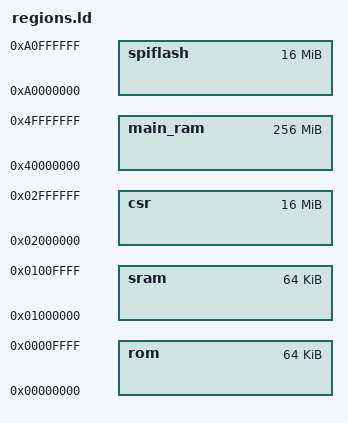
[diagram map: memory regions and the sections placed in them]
MEMORY {
	rom : ORIGIN = 0x00000000, LENGTH = 0x00010000
	sram : ORIGIN = 0x01000000, LENGTH = 0x00010000
	csr : ORIGIN = 0x02000000, LENGTH = 0x01000000
	main_ram : ORIGIN = 0x40000000, LENGTH = 0x10000000
	spiflash : ORIGIN = 0xa0000000, LENGTH = 0x01000000
}
